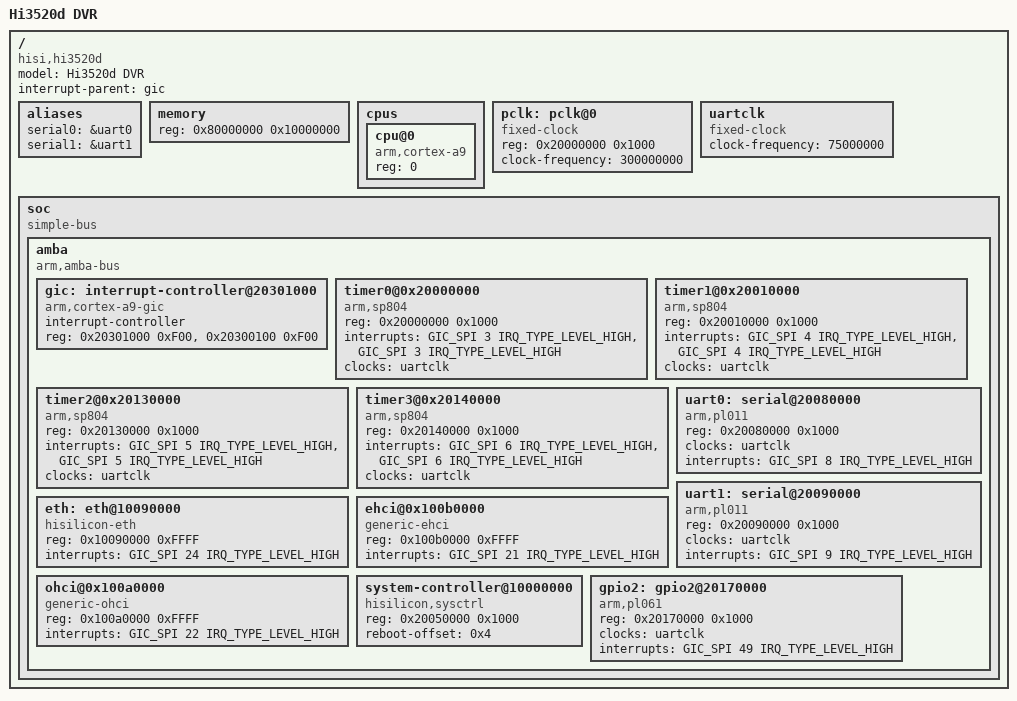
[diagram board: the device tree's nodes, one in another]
/dts-v1/;
#include <dt-bindings/interrupt-controller/arm-gic.h>

/ {
    model = "Hi3520d DVR";
    compatible = "hisi,hi3520d";
    interrupt-parent = <&gic>;
    #address-cells = <1>;
	#size-cells = <1>;

    aliases {
		serial0 = &uart0;
		serial1 = &uart1;
	};

    memory {
        device_type = "memory";
        reg = <0x80000000 0x10000000>;
    };
    
    cpus {
        #address-cells = <1>;
		#size-cells = <0>;
        cpu@0 {
            compatible = "arm,cortex-a9";
            device_type = "cpu";
			reg = <0>;
        };
    };

    pclk: pclk@0 {
		#clock-cells = <0>;
		compatible = "fixed-clock";
        reg = <0x20000000 0x1000>;
		clock-frequency = <300000000>;
	};

    uartclk: uartclk {
		#clock-cells = <0>;
		compatible = "fixed-clock";
		clock-frequency = <75000000>;
	};



    soc: soc {
        #address-cells = <1>;
		#size-cells = <1>;
        compatible = "simple-bus";

        /* child and parent address space 1:1 mapped */
        ranges;

        amba {
			#address-cells = <1>;
			#size-cells = <1>;
			compatible = "arm,amba-bus";
			ranges;

            gic: interrupt-controller@20301000 {
                compatible = "arm,cortex-a9-gic";
                interrupt-controller;
                #interrupt-cells = <3>;
                #address-cells = <0>;
                /*arm,routable-irqs = <64>;*/
                /*  gic dist base, gic cpu base*/
                reg = <0x20301000 0xF00>, <0x20300100 0xF00>; //cpu
            };

            timer0@0x20000000 {
			    compatible = "arm,sp804", "arm,primecell";
			    reg = <0x20000000 0x1000>;
			    interrupts = <GIC_SPI 3 IRQ_TYPE_LEVEL_HIGH>, <GIC_SPI 3 IRQ_TYPE_LEVEL_HIGH>;
			    clocks = <&uartclk>;
			    clock-names = "apb_pclk";
		    };

            timer1@0x20010000 {
			    compatible = "arm,sp804", "arm,primecell";
			    reg = <0x20010000 0x1000>;
			    interrupts = <GIC_SPI 4 IRQ_TYPE_LEVEL_HIGH>, <GIC_SPI 4 IRQ_TYPE_LEVEL_HIGH>;
			    clocks = <&uartclk>;
			    clock-names = "apb_pclk";
		    };

            timer2@0x20130000 {
			    compatible = "arm,sp804", "arm,primecell";
			    reg = <0x20130000 0x1000>;
			    interrupts = <GIC_SPI 5 IRQ_TYPE_LEVEL_HIGH>, <GIC_SPI 5 IRQ_TYPE_LEVEL_HIGH>;
			    clocks = <&uartclk>;
			    clock-names = "apb_pclk";
		    };

            timer3@0x20140000 {
			    compatible = "arm,sp804", "arm,primecell";
			    reg = <0x20140000 0x1000>;
			    interrupts = <GIC_SPI 6 IRQ_TYPE_LEVEL_HIGH>, <GIC_SPI 6 IRQ_TYPE_LEVEL_HIGH>;
			    clocks = <&uartclk>;
			    clock-names = "apb_pclk";
		    };

            /* Make sure to subtract 32 from the actual IRQ number */
            uart0: serial@20080000 {
                compatible = "arm,pl011", "arm,primecell";
                reg = <0x20080000 0x1000>;
                clocks = <&uartclk>;
                clock-names = "apb_pclk";
                interrupts = <GIC_SPI 8 IRQ_TYPE_LEVEL_HIGH>;
            };

            uart1: serial@20090000 {
                compatible = "arm,pl011", "arm,primecell";
                reg = <0x20090000 0x1000>;
                clocks = <&uartclk>; 
                clock-names = "apb_pclk";
                interrupts = <GIC_SPI 9 IRQ_TYPE_LEVEL_HIGH>;
            };

            /*sata0: sata@10080000 {
			    compatible		= "hisi,hi3520d-ahci", "generic-ahci";
			    reg			= <0x10080000 0xFFFF>;
			    interrupts		= <0 20 0>;
		    };*/

            eth: eth@10090000 {
                compatible		= "hisilicon-eth";
			    reg			= <0x10090000 0xFFFF>;
			    interrupts		= <GIC_SPI 24 IRQ_TYPE_LEVEL_HIGH>;
            };


            ehci@0x100b0000 {
			    compatible = "generic-ehci";
			    reg = < 0x100b0000 0xFFFF >;
			    interrupts = < GIC_SPI 21 IRQ_TYPE_LEVEL_HIGH >;
		    };

            ohci@0x100a0000 {
                compatible = "generic-ohci";
			    reg = < 0x100a0000 0xFFFF >;
			    interrupts = < GIC_SPI 22 IRQ_TYPE_LEVEL_HIGH >;
		    };

            system-controller@10000000 {
			    compatible = "hisilicon,sysctrl";
			    reg = <0x20050000 0x1000>;
			    reboot-offset = <0x4>;
		    };

            gpio2: gpio2@20170000 {
                compatible = "arm,pl061", "arm,primecell";
			    reg = <0x20170000 0x1000>;
                clocks = <&uartclk>;
			    clock-names = "apb_pclk";
                #gpio-cells = <2>;
                interrupts = <GIC_SPI 49 IRQ_TYPE_LEVEL_HIGH>;
			    #interrupt-cells = <2>;
            };

            /*rtc: rtc@20060000 {
                compatible = "hisi,hi3520d-rtc";
                reg = <0x20060000 0xFFFF>;
            };*/
        };
    };
   
};
